# GCT301S register map
Vendor: SZGC; Series: GCT301S; File version: 1.2
CPU: CM0 r0p0, little endian, no MPU, no FPU, 2 interrupt priority bits
Registers are 32-bit, read-write, reset 0x0 unless marked. A register's access mark holds for its fields unless they carry their own. Offsets are from the block's base; [hi:lo] are bit positions; {n}, {i} and the like mark numbered series; 'fields as' and 'values as' point back to an identical list.

## RTC
Base 0x40000000
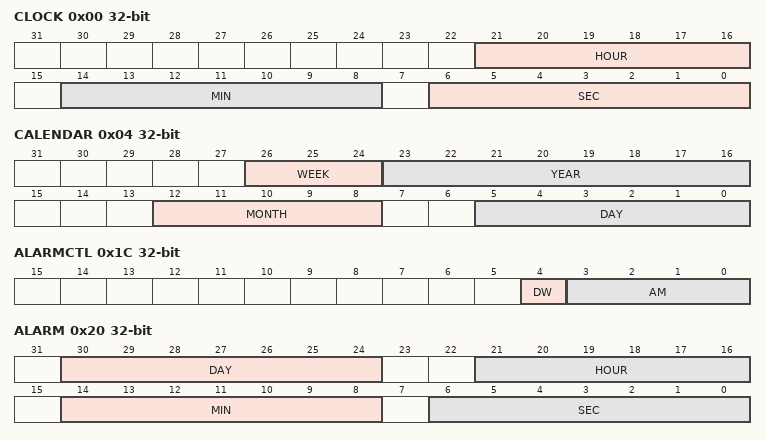
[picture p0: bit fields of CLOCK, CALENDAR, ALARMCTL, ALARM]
0x00 CLOCK
  [21:16] HOUR, [14:8] MIN, [6:0] SEC
0x04 CALENDAR
  [26:24] WEEK, [23:16] YEAR, [12:8] MONTH, [5:0] DAY
0x08 STATUS ro
  [0] VALIDITY
0x0C LOAD
  [0] LOAD_EN
0x10 LATCH
  [0] LATCH_EN
0x14 ACSEL — Adjust cycle selection
  [1:0] AC
0x18 ADJUST — Adjustment amount
  [8:0] ADJ
0x1C ALARMCTL — Alarm control
  [4] DW, [3:0] AM
0x20 ALARM
  [30:24] DAY, [21:16] HOUR, [14:8] MIN, [6:0] SEC
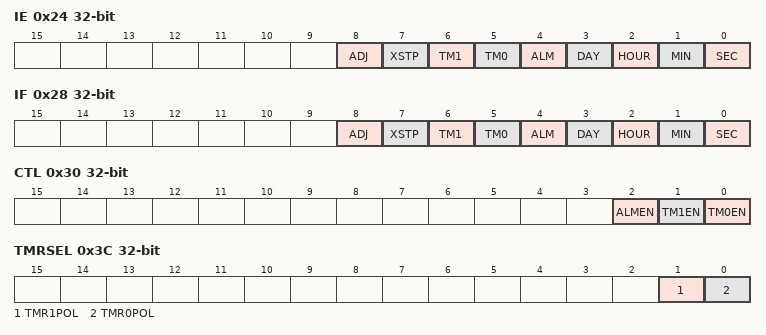
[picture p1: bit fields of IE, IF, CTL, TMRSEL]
0x24 IE — Interrupt enable
  [8] ADJ, [7] XSTP, [6] TM1, [5] TM0, [4] ALM, [3] DAY, [2] HOUR, [1] MIN, [0] SEC
0x28 IF — Interrupt flag
  fields as IE
0x30 CTL — Control
  [2] ALMEN, [1] TM1EN, [0] TM0EN
0x34 TMR0 — Timer 0 initial value
  [7:0] INI
0x38 TMR1 — Timer 1 initial value
  [7:0] INI
0x3C TMRSEL — Timer polarity
  [1] TMR1POL, [0] TMR0POL
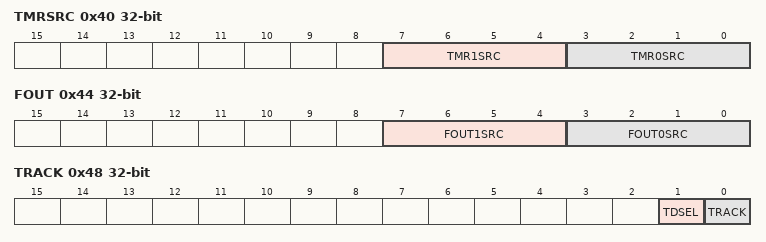
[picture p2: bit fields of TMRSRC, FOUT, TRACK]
0x40 TMRSRC — Timer clock source
  [7:4] TMR1SRC, [3:0] TMR0SRC
0x44 FOUT — FOUT source
  [7:4] FOUT1SRC, [3:0] FOUT0SRC
0x48 TRACK — Tracking control
  [1] TDSEL, [0] TRACK
0x4C TCNT — Track count
  [20:0] CNT
0x50 FDIV — 16MHz clock adjustment
  [11:0] DIV
{0x54+4i} RAM[{i}] (i=0..5)

## SPI
Base 0x4001A000
0x00 DATA
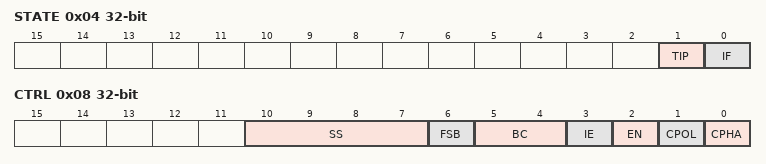
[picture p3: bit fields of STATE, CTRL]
0x04 STATE
  [1] TIP ro, [0] IF
0x08 CTRL — Control
  [10:7] SS, [6] FSB, [5:4] BC, [3] IE, [2] EN, [1] CPOL, [0] CPHA
0x0C CRSEL — Clock rate selection
  [2:0] CR

## ADC
Base 0x4000A000
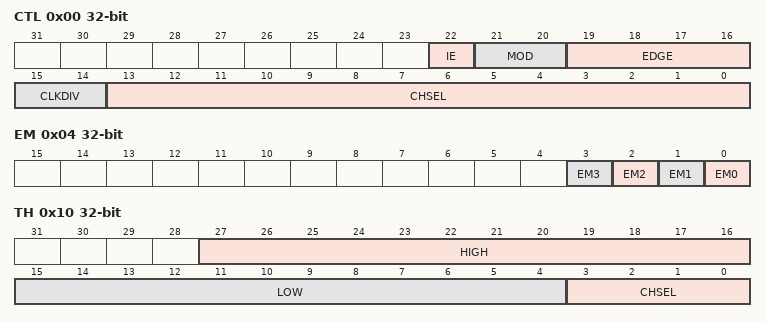
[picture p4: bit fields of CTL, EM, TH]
0x00 CTL — Control
  [22] IE, [21:20] MOD, [19:16] EDGE, [15:14] CLKDIV, [13:0] CHSEL
0x04 EM — Mask bits for external events
  [n] EM{n} (n=0..3)
0x08 START — Start ADC conversion
  [0] ON
0x0C STA ro — ADC conversion status
  [0] DONE
0x10 TH — Threshold values
  [27:16] HIGH, [15:4] LOW, [3:0] CHSEL
{0x14+4i} DR[{i}] (i=0..13) — ADC data

## LCD — LCD controller
Base 0x40008000
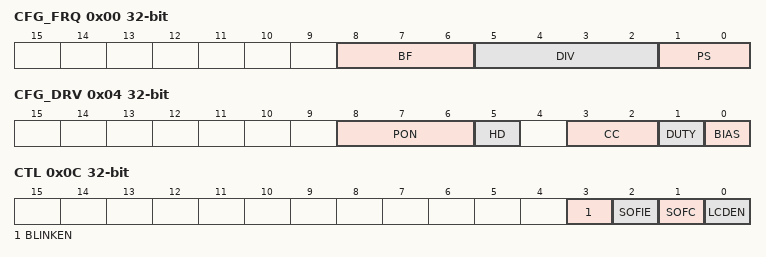
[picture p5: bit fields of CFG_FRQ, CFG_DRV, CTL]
0x00 CFG_FRQ — Clock prescaler and divider configuration
  [8:6] BF, [5:2] DIV, [1:0] PS
0x04 CFG_DRV — Driver configuration
  [8:6] PON, [5] HD, [3:2] CC, [1] DUTY, [0] BIAS
0x08 IRQ ro — Interrupt status flag
  [0] SOF
0x0C CTL — Control
  [3] BLINKEN, [2] SOFIE, [1] SOFC, [0] LCDEN
0x10 SEGM 26-bit — Segment mask
{0x14+4i} BUF[{i}] (i=0..7) 26-bit — Display buffers

## UART0
Base 0x40010000
Same registers: UART1 0x40011000, UART2 0x40012000, UART3 0x40013000, UART4 0x40014000, UART5 0x40015000
0x00 DATA — Data buffer
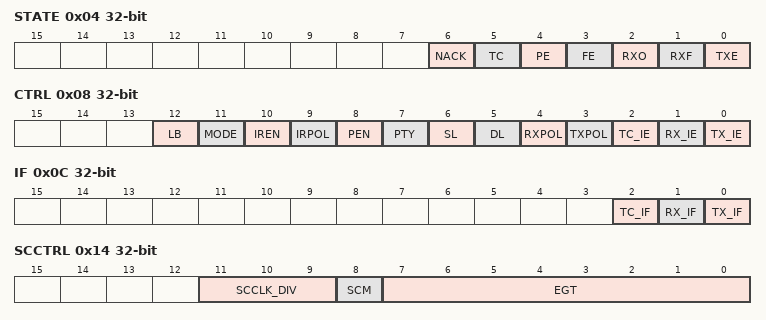
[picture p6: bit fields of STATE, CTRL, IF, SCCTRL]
0x04 STATE
  [6] NACK, [5] TC ro, [4] PE, [3] FE, [2] RXO, [1] RXF ro, [0] TXE ro
0x08 CTRL — Control
  [12] LB, [11] MODE, [10] IREN, [9] IRPOL, [8] PEN, [7] PTY, [6] SL, [5] DL, [4] RXPOL, [3] TXPOL, [2] TC_IE, [1] RX_IE, [0] TX_IE
0x0C IF — Interrupt flag
  [2] TC_IF, [1] RX_IF, [0] TX_IF
0x10 BAUD — Baud rate control
0x14 SCCTRL — Smartcard mode control
  [11:9] SCCLK_DIV, [8] SCM, [7:0] EGT
0x18 SCCLKEN — Smartcard clock enable
0x1C CLKEN — UART clock enable
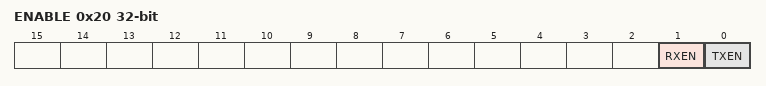
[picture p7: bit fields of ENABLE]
0x20 ENABLE — UART enable
  [1] RXEN, [0] TXEN

## CFLASH — Code Flash controller
Base 0x40017000
Same registers: DFLASH 0x40018000
0x00 KEY — Erase/Program key
0x04 NVRP — NVR protection
0x08 ERASCTR — Sector erase index
  [8:0] SCTERAI
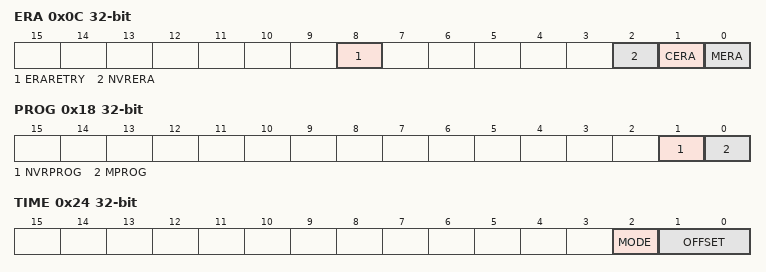
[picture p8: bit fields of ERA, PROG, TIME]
0x0C ERA — Erase control
  [8] ERARETRY, [2] NVRERA, [1] CERA, [0] MERA
0x10 PROGADDR — Byte address to program
  [16:0] PROGRADDR
0x14 PROGDATA — Byte data to program
  [7:0] PROGDATA
0x18 PROG — Program control
  [1] NVRPROG, [0] MPROG
0x1C IE — Interrupt enable
  [0] FIE
0x20 IF — Status flag
  [0] FIF
0x24 TIME — Time offset
  [2] MODE, [1:0] OFFSET

## TIMER0
Base 0x40001000
Same registers: TIMER1 0x40002000, TIMER2 0x40003000, TIMER3 0x40004000, TIMER4 0x40005000
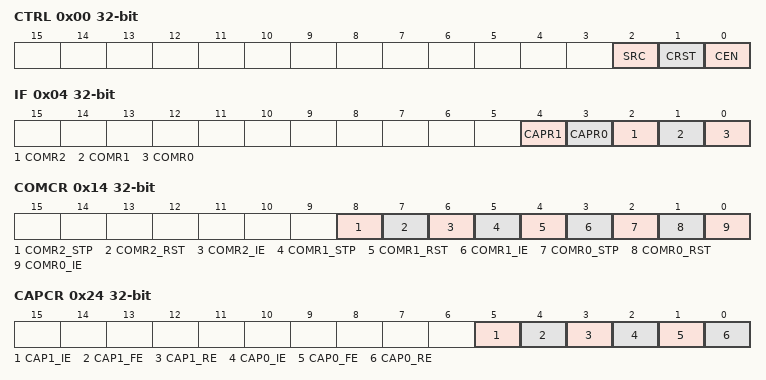
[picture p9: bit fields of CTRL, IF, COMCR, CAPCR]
0x00 CTRL — Control
  [2] SRC, [1] CRST, [0] CEN
0x04 IF — Interrupt status flag
  [4] CAPR1, [3] CAPR0, [2] COMR2, [1] COMR1, [0] COMR0
0x08 CNT — Count
0x0C PR — Prescale
0x10 PS — Prescale counter
0x14 COMCR — Compare control
  [8] COMR2_STP, [7] COMR2_RST, [6] COMR2_IE, [5] COMR1_STP, [4] COMR1_RST, [3] COMR1_IE, [2] COMR0_STP, [1] COMR0_RST, [0] COMR0_IE
{0x18+4i} COMR{i} (i=0..2) — Compare {i}
0x24 CAPCR — Capture control
  [5] CAP1_IE, [4] CAP1_FE, [3] CAP1_RE, [2] CAP0_IE, [1] CAP0_FE, [0] CAP0_RE
0x28 CAPR0 — Capture 0
0x2C CAPR1 — Capture 1
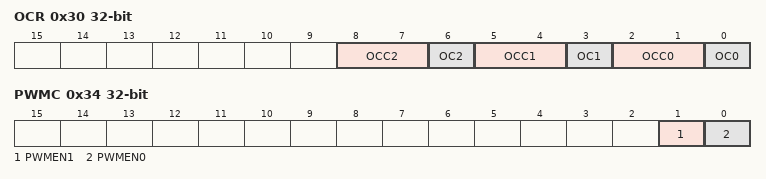
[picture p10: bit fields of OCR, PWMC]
0x30 OCR — Output compare
  [8:7] OCC2, [6] OC2, [5:4] OCC1, [3] OC1, [2:1] OCC0, [0] OC0
0x34 PWMC — PWM control
  [1] PWMEN1, [0] PWMEN0
0x38 DBG — Debug halt
  [0] DBG_HALT

## GPIOA
Base 0x40080000
Same registers: GPIOB 0x40081000, GPIOC 0x40082000
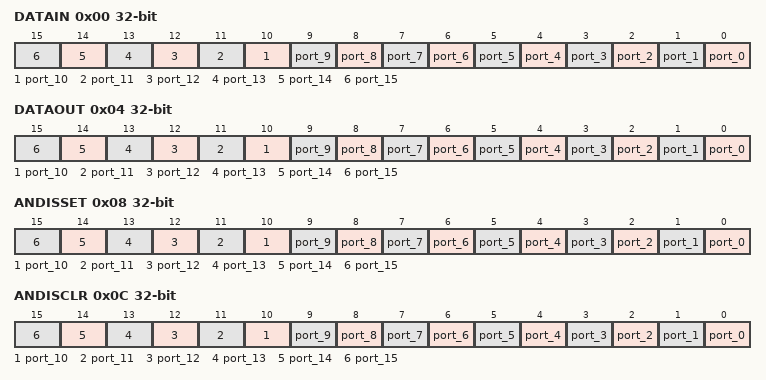
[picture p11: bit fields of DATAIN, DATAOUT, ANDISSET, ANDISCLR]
0x00 DATAIN ro — Input pin
  [n] port_{n} (n=0..15)
0x04 DATAOUT — Output latch
  [n] port_{n} (n=0..15)
0x08 ANDISSET — Analog IO disable set
  [n] port_{n} (n=0..15)
0x0C ANDISCLR wo — Analog IO disable clear
  [n] port_{n} (n=0..15)
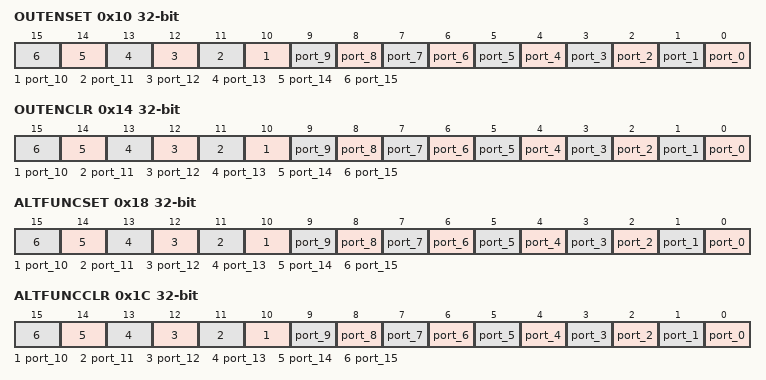
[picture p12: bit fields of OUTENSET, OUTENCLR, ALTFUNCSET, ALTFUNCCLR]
0x10 OUTENSET — Output enable set
  [n] port_{n} (n=0..15)
0x14 OUTENCLR wo — Output enable clear
  [n] port_{n} (n=0..15)
0x18 ALTFUNCSET — Alternate function enable set
  [n] port_{n} (n=0..15)
0x1C ALTFUNCCLR wo — Alternate function enable clear
  [n] port_{n} (n=0..15)
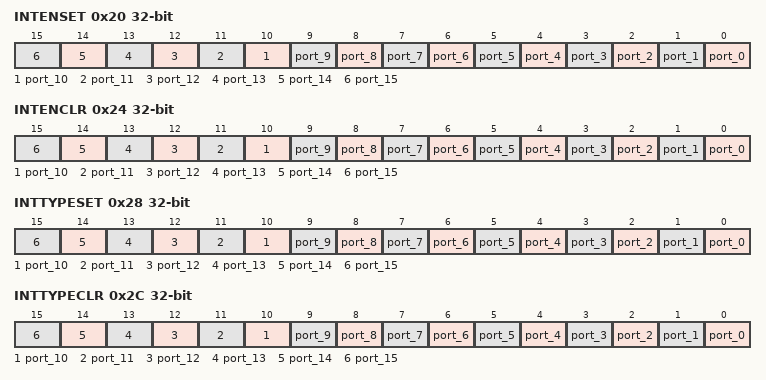
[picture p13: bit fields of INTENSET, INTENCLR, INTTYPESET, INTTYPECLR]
0x20 INTENSET — Interrupt enable set
  [n] port_{n} (n=0..15)
0x24 INTENCLR wo — Interrupt enable clear
  [n] port_{n} (n=0..15)
0x28 INTTYPESET — Interrupt type set
  [n] port_{n} (n=0..15)
0x2C INTTYPECLR wo — Interrupt type clear
  [n] port_{n} (n=0..15)
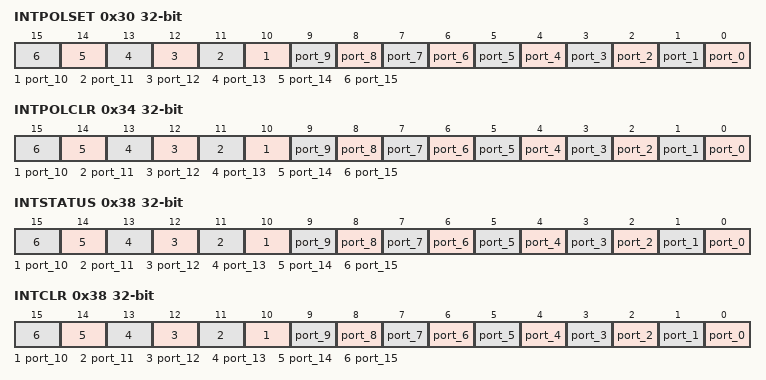
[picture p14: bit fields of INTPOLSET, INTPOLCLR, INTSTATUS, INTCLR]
0x30 INTPOLSET — Interrupt polarity set
  [n] port_{n} (n=0..15)
0x34 INTPOLCLR wo — Interrupt polarity clear
  [n] port_{n} (n=0..15)
0x38 INTSTATUS ro — Interrupt status
  [n] port_{n} (n=0..15)
0x38 INTCLR wo (alternate view of INTSTATUS) — Interrupt status
  [n] port_{n} (n=0..15)
0x3C BSCR wo — Bit set/clear
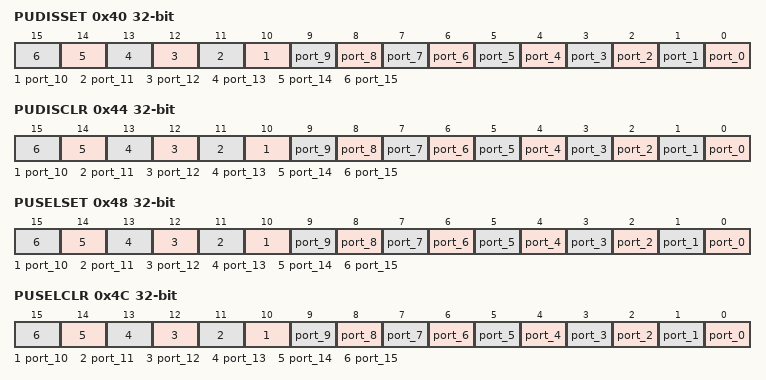
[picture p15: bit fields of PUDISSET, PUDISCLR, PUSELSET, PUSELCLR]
0x40 PUDISSET — Pullup disable set
  [n] port_{n} (n=0..15)
0x44 PUDISCLR wo — Pullup disable clear
  [n] port_{n} (n=0..15)
0x48 PUSELSET — Pullup select set
  [n] port_{n} (n=0..15)
0x4C PUSELCLR wo — Pullup select clear
  [n] port_{n} (n=0..15)
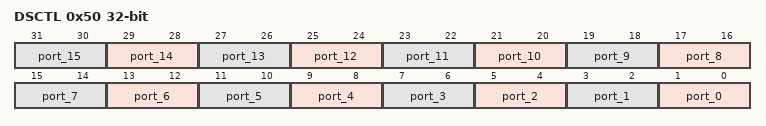
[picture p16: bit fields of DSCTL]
0x50 DSCTL — Drive strength control
  [2n+1:2n] port_{n} (n=0..15)
{0x400+4i} LB_MASKED[{i}] (i=0..255) — Lower byte mask access
{0x800+4i} UB_MASKED[{i}] (i=0..255) — Upper byte mask access
